# S32K324_M7 register map
Vendor: NXP Semiconductors; File version: 1.1
CPU: CM7 r0p1, little endian, MPU, FPU, VTOR, 4 interrupt priority bits
Registers are 32-bit, read-write, reset 0x0 unless marked. A register's access mark holds for its fields unless they carry their own. Offsets are from the block's base; [hi:lo] are bit positions; {n}, {i} and the like mark numbered series; 'fields as' and 'values as' point back to an identical list.

## BCTU
Base 0x40084000
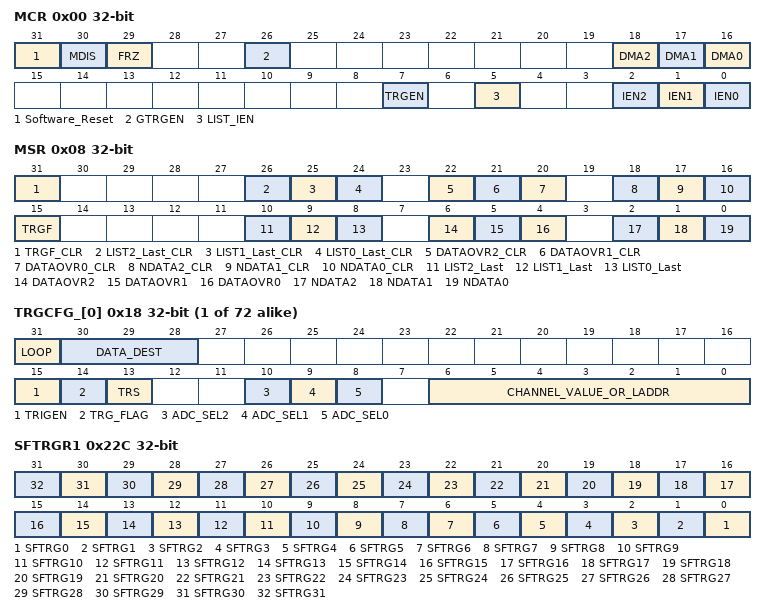
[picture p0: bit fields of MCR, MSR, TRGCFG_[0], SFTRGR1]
0x00 MCR — Module Configuration
  [31] Software_Reset
    0=deasserted (Deasserts); 1=asserted (Asserts)
  [30] MDIS — Module Disable
    0=normal (Enable (normal operation)); 1=low_power (Disable (low-power operation))
  [29] FRZ — Debug Freeze
    0=Disables; 1=Enables
  [26] GTRGEN — Global Trigger Enable
    0=disable; 1=enable
  [18] DMA2 — Enable ADC2DR DMA
    0=disable; 1=enable
  [17] DMA1 — Enable ADC1DR DMA
    0=disable; 1=enable
  [16] DMA0 — Enable ADC0DR DMA
    0=disable; 1=enable
  [7] TRGEN — Trigger Interrupt Request Enable
    0=disable; 1=enable
  [5] LIST_IEN — CL Interrupt Enable
    0=disable; 1=enable
  [2] IEN2 — Interrupt Enable For ADC2DR
    0=disable; 1=enable
  [1] IEN1 — Interrupt Enable For ADC1DR
    0=disable; 1=enable
  [0] IEN0 — Interrupt Enable For ADC0DR
    0=disable; 1=enable
0x08 MSR — Module Status
  [31] TRGF_CLR — TRGF Clear
    0=no_action; 1=clear (Changes to 0)
  [26] LIST2_Last_CLR — CL 2 Last Clear
    0=no_action; 1=write (Changes to 0)
  [25] LIST1_Last_CLR — CL 1 Last Clear
    0=no_action; 1=write (Changes to 0)
  [24] LIST0_Last_CLR — CL 0 Last Clear
    0=no_action; 1=write (Changes to 0)
  [22] DATAOVR2_CLR — DATAOVR2 Clear
    0=no_action; 1=write (Changes to 0)
  [21] DATAOVR1_CLR — DATAOVR1 Clear
    0=no_action; 1=write (Changes to 0)
  [20] DATAOVR0_CLR — DATAOVR0 Clear
    0=no_action; 1=write (Changes to 0)
  [18] NDATA2_CLR — New Data Clear
    0=no_action; 1=write (Changes to 0)
  [17] NDATA1_CLR — New Data Clear
    0=no_action; 1=write (Changes to 0)
  [16] NDATA0_CLR — New Data Clear
    0=no_action; 1=write (Changes to 0)
  [15] TRGF ro — Trigger Flag
    0=not_triggered (No ADC triggered); 1=triggered (An ADC was triggered)
  [10] LIST2_Last ro — CL 2 Last Conversion
    0=not_complete (Last conversion not complete); 1=conversion_complete (Last conversion complete)
  [9] LIST1_Last ro — CL 1 Last Conversion
    values as LIST2_Last
  [8] LIST0_Last ro — CL 0 Last Conversion
    values as LIST2_Last
  [6] DATAOVR2 ro — Data Overrun 2
    0=not_overwritten (Data not overwritten); 1=overwritten (Data overwritten)
  [5] DATAOVR1 ro — Data Overrun 1
    values as DATAOVR2
  [4] DATAOVR0 ro — Data Overrun 0
    values as DATAOVR2
  [2] NDATA2 ro — New Data 2
    0=not_available; 1=available
  [1] NDATA1 ro — New Data 1
    0=not_available; 1=available
  [0] NDATA0 ro — New Data 0
    0=not_available; 1=available
{0x18+4i} TRGCFG_[{i}] (i=0..71) — Trigger Configuration
  [31] LOOP
    0=disable; 1=enable
  [30:28] DATA_DEST — Data Destination
    0=ADC-specific data registers; 1=fifo1; 2=fifo2
  [15] TRIGEN — Trigger Enable
    0=disable; 1=enable
  [14] TRG_FLAG write-1-clears — Trigger Flag
    on write: 0=write_zero (No action); 1=write_one (Changes to 0)
  [13] TRS — Trigger Resolution
    0=Single conversion; 1=cl (CL conversions)
  [10] ADC_SEL2 — ADC Select 2
    0=not_selected (Deselects); 1=selected (Selects)
  [9] ADC_SEL1 — ADC Select 1
    0=not_selected (Deselects); 1=selected (Selects)
  [8] ADC_SEL0 — ADC Select 0
    0=not_selected (Deselects); 1=selected (Selects)
  [6:0] CHANNEL_VALUE_OR_LADDR — Channel or CL Address
0x228 WRPROT — Write Protection
  [3:0] PROTEC_CODE — Protection Code
    0=Enable protection; 9=disable_one_cycle (Disable protection for one write cycle); 10=disable_permanent (Disable protection permanently)
0x22C SFTRGR1 — Software Trigger 1
  [all] fields
    0=no_effect; 1=Trigger conversion
  [n] SFTRG{n} (n=0..31) — Software Trigger {n}
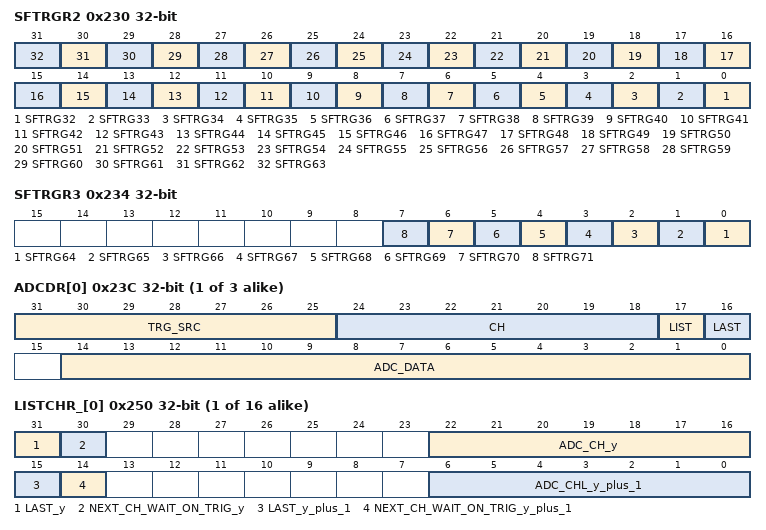
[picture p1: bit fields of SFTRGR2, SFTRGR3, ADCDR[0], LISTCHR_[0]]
0x230 SFTRGR2 — Software Trigger 2
  [all] fields
    0=no_effect; 1=Trigger conversion
  [n-32] SFTRG{n} (n=32..63) — Software Trigger {n}
0x234 SFTRGR3 — Software Trigger 3
  [all] fields
    0=no_effect; 1=Trigger conversion
  [n-64] SFTRG{n} (n=64..71) — Software Trigger {n}
{0x23C+4i} ADCDR[{i}] (i=0..2) ro — ADCn Result Data
  [31:25] TRG_SRC — Trigger Source
  [24:18] CH — Channel
  [17] LIST
    0=Single conversion; 1=cl
  [16] LAST
    0=not_last (Not the last conversion of a CL, or not a CL conversion); 1=Last conversion of a CL
  [14:0] ADC_DATA
0x24C LISTSTAR ro reset 0x20 — CL Size Status
  [7:0] LISTSZ — CL Size
{0x250+4i} LISTCHR_[{i}] (i=0..15) — CL Channel Address
  [31] LAST_y — Last Channel
    0=not_last; 1=Last channel in CL
  [30] NEXT_CH_WAIT_ON_TRIG_y — Next Channel Wait For Trigger
    0=continuous (CL executes continuously); 1=stop_after_current (CL stops executing)
  [22:16] ADC_CH_y — ADC Channel Selection
  [15] LAST_y_plus_1 — Last Channel Plus 1
    0=not_last (Not next-to-last); 1=last (Next-to-last channel in CL)
  [14] NEXT_CH_WAIT_ON_TRIG_y_plus_1 — Next Channel Wait For Trigger Plus 1
    values as NEXT_CH_WAIT_ON_TRIG_y
  [6:0] ADC_CHL_y_plus_1 — ADC Channel Selection Plus 1
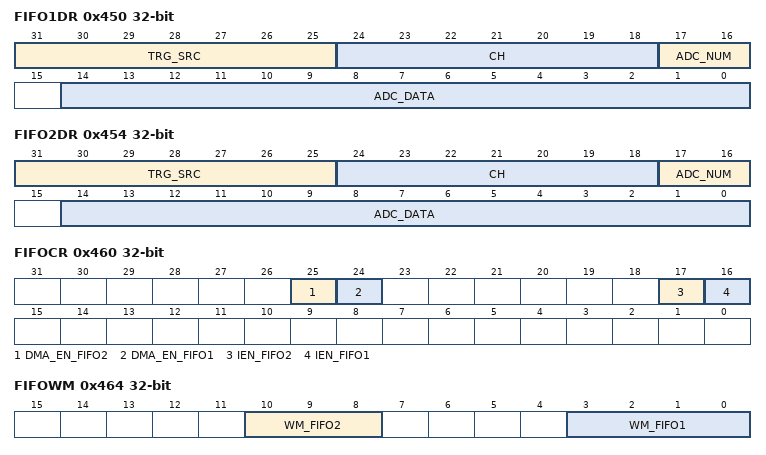
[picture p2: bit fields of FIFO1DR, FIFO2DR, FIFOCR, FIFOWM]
0x450 FIFO1DR ro — FIFO Result Data
  [31:25] TRG_SRC — Trigger Source
  [24:18] CH — Channel
  [17:16] ADC_NUM — ADC Number
    {v}=adc_{v} (v=0..3)
  [14:0] ADC_DATA
0x454 FIFO2DR ro — FIFO Result Data
  fields as FIFO1DR
0x460 FIFOCR — FIFO Control
  [all] fields
    0=disable; 1=enable
  [25] DMA_EN_FIFO2 — FIFO2 DMA Enable
  [24] DMA_EN_FIFO1 — FIFO1 DMA Enable
  [17] IEN_FIFO2 — FIFO2 Interrupt Enable
  [16] IEN_FIFO1 — FIFO1 Interrupt Enable
0x464 FIFOWM — FIFO Watermark Configuration
  [10:8] WM_FIFO2 — FIFO2 Watermark Level
  [3:0] WM_FIFO1 — FIFO1 Watermark Level
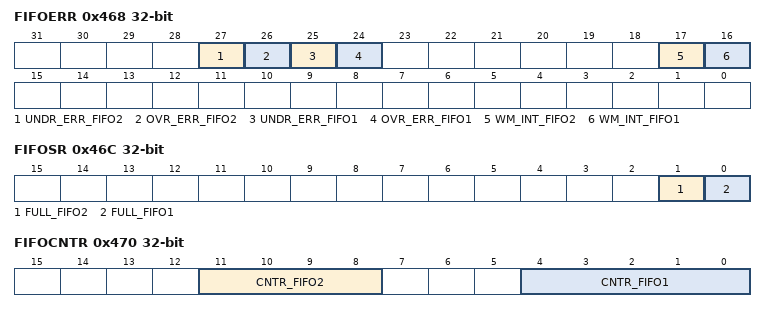
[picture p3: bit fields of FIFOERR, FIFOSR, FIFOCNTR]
0x468 FIFOERR write-1-clears — FIFO Error/Status
  [27] UNDR_ERR_FIFO2 write-1-clears — Underrun Error Flag
    0=no_underrun; 1=underrun
  [26] OVR_ERR_FIFO2 write-1-clears — Overrun Error Flag
    0=no_overrun; 1=overrun
  [25] UNDR_ERR_FIFO1 write-1-clears — Underrun Error Flag
    0=no_underrun; 1=underrun
  [24] OVR_ERR_FIFO1 write-1-clears — Overrun Error Flag
    0=no_overrun; 1=overrun
  [17] WM_INT_FIFO2 write-1-clears — FIFO Watermark Interrupt Status
    0=not_exceed (Does not exceed watermark); 1=Exceeds watermark
  [16] WM_INT_FIFO1 write-1-clears — FIFO Watermark Interrupt Status
    values as WM_INT_FIFO2
0x46C FIFOSR ro — FIFO Status
  [1] FULL_FIFO2 — FIFO Full
    0=not_full; 1=full
  [0] FULL_FIFO1 — FIFO Full
    0=not_full; 1=full
0x470 FIFOCNTR ro — FIFO Counter
  [11:8] CNTR_FIFO2 — FIFO2 Counter
  [4:0] CNTR_FIFO1 — FIFO1 Counter
